# SF32LB55x register map
File version: 1.0
CPU: CM33 r0p1, little endian, MPU, FPU, 3 interrupt priority bits
Registers are 32-bit, read-write, reset 0x0 unless marked. A register's access mark holds for its fields unless they carry their own. Offsets are from the block's base; [hi:lo] are bit positions; {n}, {i} and the like mark numbered series.

## LPSYS_CFG
Base 0x4004F000
0x00 SWCR — SW Control Register
  [0] SWSEL — 0 - SWD connected to HCPU 1 - SWD connected to LCPU
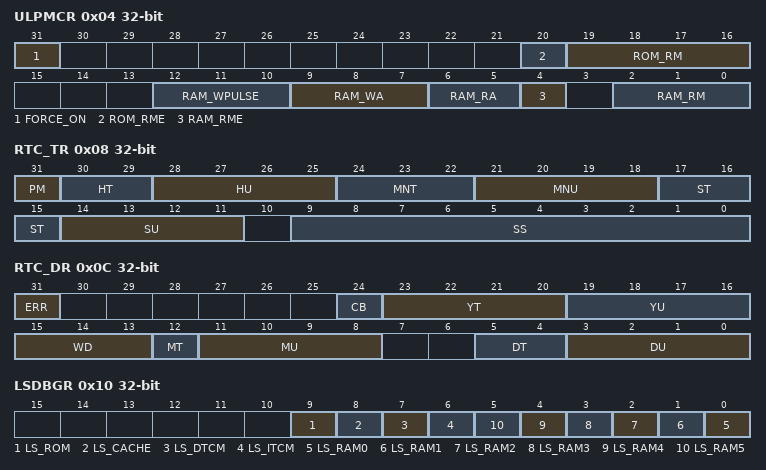
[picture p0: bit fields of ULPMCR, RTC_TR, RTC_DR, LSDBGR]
0x04 ULPMCR — ULP Memory Control register
  [31] FORCE_ON — reserved for debug
  [20] ROM_RME — reserved for debug
  [19:16] ROM_RM — reserved for debug
  [12:10] RAM_WPULSE — reserved for debug
  [9:7] RAM_WA — reserved for debug
  [6:5] RAM_RA — reserved for debug
  [4] RAM_RME — reserved for debug
  [2:0] RAM_RM — reserved for debug
0x08 RTC_TR — Mirrored RTC Time Register
  [31] PM — AM/PM notation 0: AM 1: PM
  [30:29] HT — Hour tens in BCD format
  [28:25] HU — Hour units in BCD format
  [24:22] MNT — Minute tens in BCD format
  [21:18] MNU — Minute units in BCD format
  [17:15] ST — Second tens in BCD format
  [14:11] SU — Second units in BCD format
  [9:0] SS — Sub-second counter
0x0C RTC_DR — Mirrored RTC Date Register
  [31] ERR — reserved for debug
  [24] CB — Century flag
  [23:20] YT — Year tens in BCD format
  [19:16] YU — Year units in BCD format
  [15:13] WD — Week day units 000: forbidden 001: Monday ... 111: Sunday
  [12] MT — Month tens in BCD format
  [11:8] MU — Month units in BCD format
  [5:4] DT — Date tens in BCD format
  [3:0] DU — Date units in BCD format
0x10 LSDBGR — Light Sleep Debug Register
  [9] LS_ROM — reserved for debug
  [8] LS_CACHE — reserved for debug
  [7] LS_DTCM — reserved for debug
  [6] LS_ITCM — reserved for debug
  [n] LS_RAM{n} (n=0..5) — reserved for debug
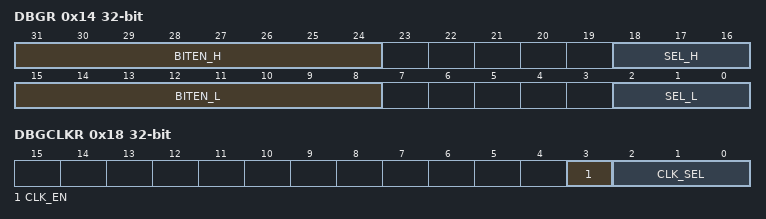
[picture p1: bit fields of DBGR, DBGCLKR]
0x14 DBGR — Debug Select Register
  [31:24] BITEN_H — reserved for debug
  [18:16] SEL_H — reserved for debug
  [15:8] BITEN_L — reserved for debug
  [2:0] SEL_L — reserved for debug
0x18 DBGCLKR — Debug Clock Register
  [3] CLK_EN — reserved for debug
  [2:0] CLK_SEL — reserved for debug

## GPADC
Base 0x40056000
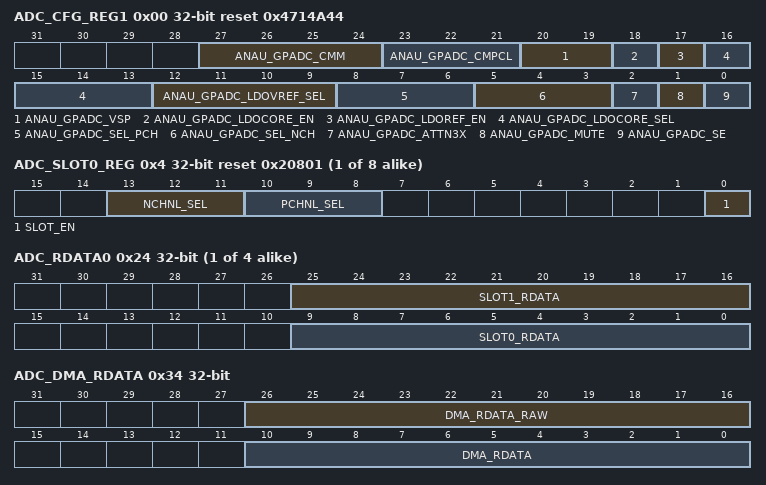
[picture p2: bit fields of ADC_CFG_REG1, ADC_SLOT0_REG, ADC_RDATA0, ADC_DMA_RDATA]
0x00 ADC_CFG_REG1 reset 0x4714A44 — ADC Analog Config Register 1
  [27:24] ANAU_GPADC_CMM — Tune CDAC CM voltage 375mV range (increasing) / 25mV step, 8: for 0.5V Vcm,in
  [23:21] ANAU_GPADC_CMPCL — Tune ADC comparator CL= 3: 40f, range: 10fF (0) ~ 80fF (7) / 10fF step
  [20:19] ANAU_GPADC_VSP — Set comparator input CM in sampling phase, 0.539V (0) / 0.578V (1) / 0.642V (2) / 0.784V (3)
  [18] ANAU_GPADC_LDOCORE_EN — Enable LDORF for ADC
  [17] ANAU_GPADC_LDOREF_EN — Enable LDORF for ADC VREF
  [16:13] ANAU_GPADC_LDOCORE_SEL — Set reference voltage for LDOCORE, range = 0.35V(0) ~ 0.65V(15), step = 20mV
  [12:9] ANAU_GPADC_LDOVREF_SEL — Set reference voltage for LDOREF, range = 0.35V(0) ~ 0.65V(15), step = 20mV
  [8:6] ANAU_GPADC_SEL_PCH — Select P-side input channel for GPADC, 0 for channel 0, 7 for channel 7, effective when force on
  [5:3] ANAU_GPADC_SEL_NCH — Select N-side input channel for GPADC, 0 for channel 0, 7 for channel 7, effective when force on
  [2] ANAU_GPADC_ATTN3X — Attenuate input voltage by 3 for GPADC
  [1] ANAU_GPADC_MUTE — Short GPADC P and N input to CMREF, i.e., VREF/2
  [0] ANAU_GPADC_SE — Set GPADC in single-ended mode, signal range at P-input: 0 ~ VREF
{0x4+4i} ADC_SLOT{i}_REG reset 0x20801 (i=0..7) — ADC Slot{i} Config Register
  [13:11] NCHNL_SEL, [10:8] PCHNL_SEL, [0] SLOT_EN
{0x24+4i} ADC_RDATA{i} (i=0..3) — ADC Read Data{i}
  [25:16] SLOT{2i+1}_RDATA, [9:0] SLOT{2i}_RDATA
0x34 ADC_DMA_RDATA — ADC Read Data For DMA
  [26:16] DMA_RDATA_RAW, [10:0] DMA_RDATA
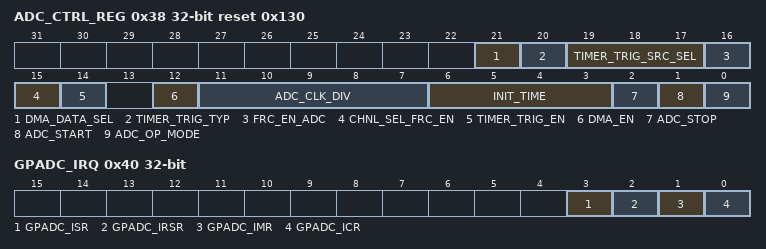
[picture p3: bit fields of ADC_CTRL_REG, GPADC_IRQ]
0x38 ADC_CTRL_REG reset 0x130 — ADC Control Register
  [21] DMA_DATA_SEL — 0: combined data 1: raw data
  [20] TIMER_TRIG_TYP — 0: pulse no edge detect needed 1: level,need edge detect
  [19:17] TIMER_TRIG_SRC_SEL
  [16] FRC_EN_ADC
  [15] CHNL_SEL_FRC_EN
  [14] TIMER_TRIG_EN
  [12] DMA_EN
  [11:7] ADC_CLK_DIV
  [6:3] INIT_TIME
  [2] ADC_STOP
  [1] ADC_START
  [0] ADC_OP_MODE — 0: finite 1: inifinite
0x40 GPADC_IRQ
  [3] GPADC_ISR, [2] GPADC_IRSR, [1] GPADC_IMR, [0] GPADC_ICR
